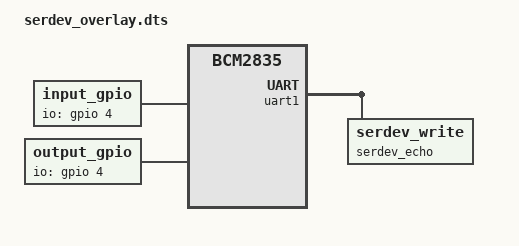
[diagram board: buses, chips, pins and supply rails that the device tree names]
/dts-v1/;
/plugin/;
/ {
	compatible = "brcm,bcm2835";
	fragment@0 {
		target-path = "/";
		__overlay__ {
			input {
				compatible = "input_gpio";
				status = "okay";
				io-gpios = <&gpio 4 0>;
			};
			output {
				compatible = "output_gpio";
				status = "okay";
				io-gpios = <&gpio 4 0>;
			};
		};
	};
	fragment@1 {
		target = <&uart1>;	
		__overlay__ {
			serdev_echo {
				compatible = "serdev_write";
				status = "okay";
				write = "Hello from NamDHay";
			};
		};
	};
};
